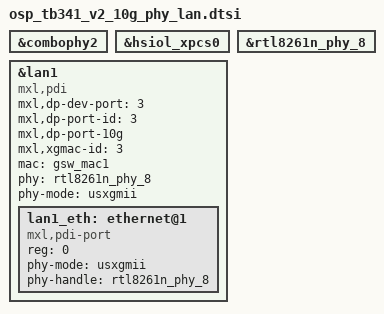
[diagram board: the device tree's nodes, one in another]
// SPDX-License-Identifier: GPL-2.0
/*
 * Copyright (C) 2023 MaxLinear, Inc.
 */

/* combo phy 2 */
&combophy2 { /* PCIe20/21, HSIOR_XPCS0/1, SATA20/21 */
	status = "okay";
};

&hsiol_xpcs0 {
	status = "okay";
};

&rtl8261n_phy_8 {
	status = "okay";
};

&lan1 {
	status = "okay";

	#address-cells = <1>;
	#size-cells = <0>;
	compatible = "mxl,pdi";
	mxl,dp-dev-port = <3>;
	mxl,dp-port-id = <3>;
	mxl,dp-port-10g;
	mxl,xgmac-id = <3>;
	mac = <&gsw_mac1>;
	phy = <&rtl8261n_phy_8>;
	phy-mode = "usxgmii";

	lan1_eth: ethernet@1 {
		compatible = "mxl,pdi-port";
		reg = <0>;
		phy-mode = "usxgmii";
		phy-handle = <&rtl8261n_phy_8>;
	};
};
